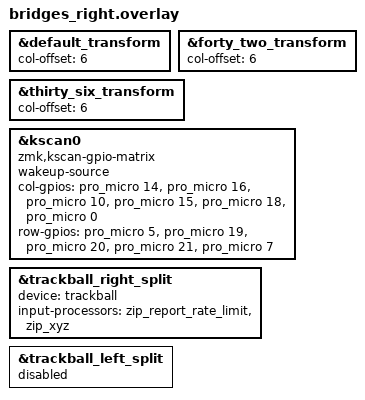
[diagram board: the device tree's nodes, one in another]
/*
 * Copyright (c) 2025 Vincent Franco
 * SPDX-License-Identifier: MIT
 */

#include "bridges.dtsi"
#include "bridges_3610.dtsi"
#include "split_input_common.dtsi"

&default_transform {
  col-offset = <6>;
};

&forty_two_transform {
  col-offset = <6>;
};

&thirty_six_transform {
  col-offset = <6>;
};

&kscan0 {
  compatible = "zmk,kscan-gpio-matrix";
  wakeup-source;

  col-gpios = <&pro_micro 14 GPIO_ACTIVE_HIGH>,
              <&pro_micro 16 GPIO_ACTIVE_HIGH>,
              <&pro_micro 10 GPIO_ACTIVE_HIGH>,
              <&pro_micro 15 GPIO_ACTIVE_HIGH>,
              <&pro_micro 18 GPIO_ACTIVE_HIGH>,
              <&pro_micro 0 GPIO_ACTIVE_HIGH>;

  row-gpios = <&pro_micro 5 (GPIO_ACTIVE_HIGH | GPIO_PULL_DOWN)>,
              <&pro_micro 19 (GPIO_ACTIVE_HIGH | GPIO_PULL_DOWN)>,
              <&pro_micro 20 (GPIO_ACTIVE_HIGH | GPIO_PULL_DOWN)>,
              <&pro_micro 21 (GPIO_ACTIVE_HIGH | GPIO_PULL_DOWN)>,
              <&pro_micro 7 (GPIO_ACTIVE_HIGH | GPIO_PULL_DOWN)>;
};

// Overrides for the input-split child node
&trackball_right_split {
  device = <&trackball>;
  input-processors = <&zip_report_rate_limit>, <&zip_xyz>;
};

&trackball_left_split {
  status = "disabled";
};

